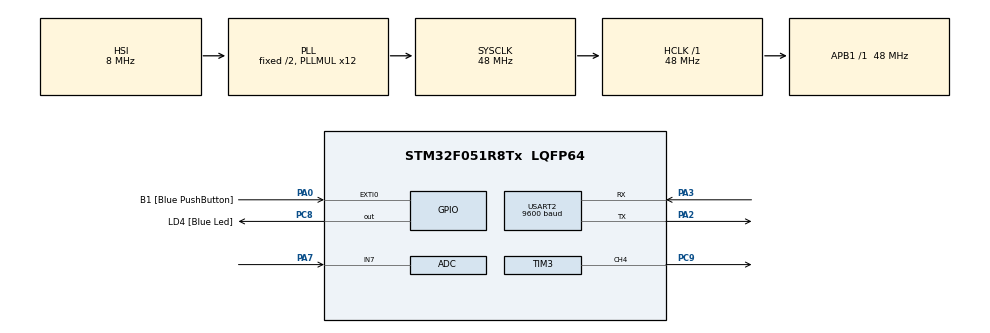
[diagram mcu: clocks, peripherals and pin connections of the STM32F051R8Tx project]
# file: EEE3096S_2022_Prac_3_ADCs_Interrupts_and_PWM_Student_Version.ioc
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Dma.ADC.1.Direction=DMA_PERIPH_TO_MEMORY
Dma.ADC.1.Instance=DMA1_Channel1
Dma.ADC.1.MemDataAlignment=DMA_MDATAALIGN_HALFWORD
Dma.ADC.1.MemInc=DMA_MINC_ENABLE
Dma.ADC.1.Mode=DMA_NORMAL
Dma.ADC.1.PeriphDataAlignment=DMA_PDATAALIGN_HALFWORD
Dma.ADC.1.PeriphInc=DMA_PINC_DISABLE
Dma.ADC.1.Priority=DMA_PRIORITY_LOW
Dma.Request0=USART2_TX
Dma.Request1=ADC
Dma.USART2_TX.0.Direction=DMA_MEMORY_TO_PERIPH
Dma.USART2_TX.0.Instance=DMA1_Channel4
Dma.USART2_TX.0.MemDataAlignment=DMA_MDATAALIGN_BYTE
Dma.USART2_TX.0.MemInc=DMA_MINC_ENABLE
Dma.USART2_TX.0.Mode=DMA_NORMAL
Dma.USART2_TX.0.PeriphDataAlignment=DMA_PDATAALIGN_BYTE
Dma.USART2_TX.0.PeriphInc=DMA_PINC_DISABLE
Dma.USART2_TX.0.Priority=DMA_PRIORITY_LOW
Mcu.Family=STM32F0
Mcu.Name=STM32F051R8Tx
Mcu.Package=LQFP64
NVIC.ADC1_COMP_IRQn=true\:0\:0\:false\:false\:true\:true\:true\:true
NVIC.DMA1_Channel1_IRQn=true\:0\:0\:false\:false\:true\:false\:true\:true
NVIC.DMA1_Channel4_5_IRQn=true\:0\:0\:false\:false\:true\:false\:true\:true
NVIC.EXTI0_1_IRQn=true\:0\:0\:false\:false\:true\:true\:true\:true
NVIC.USART2_IRQn=true\:0\:0\:false\:false\:true\:true\:true\:true
PA0.GPIO_Label=B1 [Blue PushButton]
PA0.GPIO_ModeDefaultEXTI=GPIO_MODE_IT_FALLING
PA0.Signal=GPXTI0
PA13.GPIO_Label=SWDIO
PA13.Mode=Serial_Wire
PA13.Signal=SYS_SWDIO
PA14.GPIO_Label=SWCLK
PA14.Mode=Serial_Wire
PA14.Signal=SYS_SWCLK
PA2.Mode=Asynchronous
PA2.Signal=USART2_TX
PA3.Mode=Asynchronous
PA3.Signal=USART2_RX
PA7.Mode=IN7
PA7.Signal=ADC_IN7
PB6.Signal=I2C1_SCL
PB7.Signal=I2C1_SDA
PC8.GPIO_Label=LD4 [Blue Led]
PC8.Signal=GPIO_Output
PC9.Signal=S_TIM3_CH4
PF0-OSC_IN.Mode=HSE-External-Oscillator
PF0-OSC_IN.Signal=RCC_OSC_IN
PF1-OSC_OUT.Mode=HSE-External-Oscillator
PF1-OSC_OUT.Signal=RCC_OSC_OUT
ProjectManager.HeapSize=0x200
ProjectManager.StackSize=0x400
ProjectManager.TargetToolchain=STM32CubeIDE
RCC.AHBFreq_Value=48000000
RCC.APB1Freq_Value=48000000
RCC.APB1TimFreq_Value=48000000
RCC.HCLKFreq_Value=48000000
RCC.PLLMUL=RCC_PLL_MUL12
RCC.SYSCLKFreq_VALUE=48000000
RCC.SYSCLKSource=RCC_SYSCLKSOURCE_PLLCLK
SH.S_TIM3_CH4.0=TIM3_CH4,PWM Generation4 CH4
TIM3.AutoReloadPreload=TIM_AUTORELOAD_PRELOAD_ENABLE
TIM3.Channel-PWM\ Generation4\ CH4=TIM_CHANNEL_4
TIM3.Period=47999
USART2.BaudRate=9600
USART2.VirtualMode-Asynchronous=VM_ASYNC
VP_TIM3_VS_ClockSourceINT.Mode=Internal
board=STM32F0DISCOVERY

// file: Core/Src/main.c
/* USER CODE BEGIN Header */
/**
*******************************************************
Info:		STM32 ADCs, GPIO Interrupts and PWM with HAL
Author:		Amaan Vally
*******************************************************
In this practical you will learn to use the ADC on the STM32 using the HAL.
Here, we will be measuring the voltage on a potentiometer and using its value
to adjust the brightness of the on board LEDs. We set up an interrupt to switch the
display between the blue and green LEDs.

Code is also provided to send data from the STM32 to other devices using UART protocol
by using HAL. You will need Putty or a Python script to read from the serial port on your PC.

UART Connections are as follows: 5V->5V GND->GND RXD->PA2 TXD->PA3(unused).
Open device manager and go to Ports. Plug in the USB connector with the STM powered on.
Check the port number (COMx). Open up Putty and create a new Serial session on that COMx
with baud rate of 9600.
  ******************************************************************************
  */
/* USER CODE END Header */
#include "main.h"

/* USER CODE BEGIN Includes */
#include <stdio.h>
#include <stdbool.h>

/* USER CODE END Includes */

ADC_HandleTypeDef hadc;
DMA_HandleTypeDef hdma_adc;

TIM_HandleTypeDef htim3;

UART_HandleTypeDef huart2;
DMA_HandleTypeDef hdma_usart2_tx;

/* USER CODE BEGIN PV */
uint32_t tick = 0;
uint32_t previousTick = 0;

char buff[23];
uint32_t count = 0;
uint32_t parity = 0;
bool button_pressed;
//TO DO:
//TASK 1
//Create global variables for debouncing and delay interval

/* USER CODE END PV */

void SystemClock_Config(void);
static void MX_GPIO_Init(void);
static void MX_DMA_Init(void);
static void MX_USART2_UART_Init(void);
static void MX_ADC_Init(void);
static void MX_TIM3_Init(void);
/* USER CODE BEGIN PFP */
void EXTI0_1_IRQHandler(void);
uint32_t pollADC(void);

/* USER CODE END PFP */

int main(void)
{

  /* MCU Configuration--------------------------------------------------------*/

  /* Reset of all peripherals, Initializes the Flash interface and the Systick. */
  HAL_Init();

  /* Configure the system clock */
  SystemClock_Config();

  /* Initialize all configured peripherals */
  MX_GPIO_Init();
  MX_DMA_Init();
  MX_USART2_UART_Init();
  MX_ADC_Init();
  MX_TIM3_Init();
  /* USER CODE BEGIN 2 */

  //TO DO:
  //Create variables needed in while loop

  HAL_TIM_PWM_Start(&htim3, TIM_CHANNEL_4); //Start the PWM on TIM3 Channel 4 (Green LED)
  /* USER CODE END 2 */

  /* Infinite loop */
  /* USER CODE BEGIN WHILE */
  while (1)
  {
	  //int starttime = HAL_GetTick();

	  if (button_pressed) {

		  int delay = 510;
		  uint32_t data = pollADC();
		  //uint32_t data = 0b010101010101;
		  uint32_t count1 = count;
		  int oneCount = 0;

		//Build in start bit
		buff[0] = '1';

		//Build in data
		int loop_count = 12;
	    int what_bit_i_am_testing = 0;
		while (what_bit_i_am_testing < 12) {
			if (data & 0x01) {
				buff[loop_count] = '1';
				oneCount += 1;

			}
			  else {
				buff[loop_count] = '0';
			  }

			  what_bit_i_am_testing++;
			  data = data >> 1;
			  loop_count--;
			}

		//Build in parity bit
		if (oneCount%2 == 0) {
			buff[13] = '0';
		} else {
			buff[13] = '1';
		}

		//Build in count
		loop_count = 21;
	    what_bit_i_am_testing = 0;
		while (what_bit_i_am_testing < 8) {
			if (count1 & 0x01) {
				buff[loop_count] = '1';

			}
			  else {
				buff[loop_count] = '0';
			  }

			  what_bit_i_am_testing++;
			  count1 = count1 >> 1;
			  loop_count--;
			}

		//Build in end bit
		buff[22] = '1';

		HAL_UART_Transmit(&huart2, (uint8_t *)&buff, sizeof(buff), 1000);

		//Send data
		for (int j = 0; j <= 22; j++) {
			if (buff[j] == '1') {
				HAL_GPIO_WritePin(GPIOF, GPIO_PIN_6, 1);
				HAL_GPIO_WritePin(GPIOC, GPIO_PIN_8, 1);
			    HAL_Delay(delay);
			    HAL_GPIO_WritePin(GPIOF, GPIO_PIN_6, 0);
			    HAL_GPIO_WritePin(GPIOC, GPIO_PIN_8, 0);
			} else {
				HAL_Delay(delay);
			}

		}

		count += 1;
		button_pressed = false;
	  }

    /* USER CODE END WHILE */

  }
}

void SystemClock_Config(void)
{
  RCC_OscInitTypeDef RCC_OscInitStruct = {0};
  RCC_ClkInitTypeDef RCC_ClkInitStruct = {0};

  /** Initializes the RCC Oscillators according to the specified parameters
  * in the RCC_OscInitTypeDef structure.
  */
  RCC_OscInitStruct.OscillatorType = RCC_OSCILLATORTYPE_HSI|RCC_OSCILLATORTYPE_HSI14;
  RCC_OscInitStruct.HSIState = RCC_HSI_ON;
  RCC_OscInitStruct.HSI14State = RCC_HSI14_ON;
  RCC_OscInitStruct.HSICalibrationValue = RCC_HSICALIBRATION_DEFAULT;
  RCC_OscInitStruct.HSI14CalibrationValue = 16;
  RCC_OscInitStruct.PLL.PLLState = RCC_PLL_ON;
  RCC_OscInitStruct.PLL.PLLSource = RCC_PLLSOURCE_HSI;
  RCC_OscInitStruct.PLL.PLLMUL = RCC_PLL_MUL12;
  RCC_OscInitStruct.PLL.PREDIV = RCC_PREDIV_DIV1;
  if (HAL_RCC_OscConfig(&RCC_OscInitStruct) != HAL_OK)
  {
    Error_Handler();
  }

  /** Initializes the CPU, AHB and APB buses clocks
  */
  RCC_ClkInitStruct.ClockType = RCC_CLOCKTYPE_HCLK|RCC_CLOCKTYPE_SYSCLK
                              |RCC_CLOCKTYPE_PCLK1;
  RCC_ClkInitStruct.SYSCLKSource = RCC_SYSCLKSOURCE_PLLCLK;
  RCC_ClkInitStruct.AHBCLKDivider = RCC_SYSCLK_DIV1;
  RCC_ClkInitStruct.APB1CLKDivider = RCC_HCLK_DIV1;

  if (HAL_RCC_ClockConfig(&RCC_ClkInitStruct, FLASH_LATENCY_1) != HAL_OK)
  {
    Error_Handler();
  }
}

static void MX_ADC_Init(void)
{

  ADC_ChannelConfTypeDef sConfig = {0};

  /** Configure the global features of the ADC (Clock, Resolution, Data Alignment and number of conversion)
  */
  hadc.Instance = ADC1;
  hadc.Init.ClockPrescaler = ADC_CLOCK_ASYNC_DIV1;
  hadc.Init.Resolution = ADC_RESOLUTION_12B;
  hadc.Init.DataAlign = ADC_DATAALIGN_RIGHT;
  hadc.Init.ScanConvMode = ADC_SCAN_DIRECTION_FORWARD;
  hadc.Init.EOCSelection = ADC_EOC_SINGLE_CONV;
  hadc.Init.LowPowerAutoWait = DISABLE;
  hadc.Init.LowPowerAutoPowerOff = DISABLE;
  hadc.Init.ContinuousConvMode = DISABLE;
  hadc.Init.DiscontinuousConvMode = DISABLE;
  hadc.Init.ExternalTrigConv = ADC_SOFTWARE_START;
  hadc.Init.ExternalTrigConvEdge = ADC_EXTERNALTRIGCONVEDGE_NONE;
  hadc.Init.DMAContinuousRequests = DISABLE;
  hadc.Init.Overrun = ADC_OVR_DATA_PRESERVED;
  if (HAL_ADC_Init(&hadc) != HAL_OK)
  {
    Error_Handler();
  }

  /** Configure for the selected ADC regular channel to be converted.
  */
  sConfig.Channel = ADC_CHANNEL_7;
  sConfig.Rank = ADC_RANK_CHANNEL_NUMBER;
  sConfig.SamplingTime = ADC_SAMPLETIME_1CYCLE_5;
  if (HAL_ADC_ConfigChannel(&hadc, &sConfig) != HAL_OK)
  {
    Error_Handler();
  }

}

static void MX_TIM3_Init(void)
{

  TIM_ClockConfigTypeDef sClockSourceConfig = {0};
  TIM_MasterConfigTypeDef sMasterConfig = {0};
  TIM_OC_InitTypeDef sConfigOC = {0};

  htim3.Instance = TIM3;
  htim3.Init.Prescaler = 0;
  htim3.Init.CounterMode = TIM_COUNTERMODE_UP;
  htim3.Init.Period = 47999;
  htim3.Init.ClockDivision = TIM_CLOCKDIVISION_DIV1;
  htim3.Init.AutoReloadPreload = TIM_AUTORELOAD_PRELOAD_ENABLE;
  if (HAL_TIM_Base_Init(&htim3) != HAL_OK)
  {
    Error_Handler();
  }
  sClockSourceConfig.ClockSource = TIM_CLOCKSOURCE_INTERNAL;
  if (HAL_TIM_ConfigClockSource(&htim3, &sClockSourceConfig) != HAL_OK)
  {
    Error_Handler();
  }
  if (HAL_TIM_PWM_Init(&htim3) != HAL_OK)
  {
    Error_Handler();
  }
  sMasterConfig.MasterOutputTrigger = TIM_TRGO_RESET;
  sMasterConfig.MasterSlaveMode = TIM_MASTERSLAVEMODE_DISABLE;
  if (HAL_TIMEx_MasterConfigSynchronization(&htim3, &sMasterConfig) != HAL_OK)
  {
    Error_Handler();
  }
  sConfigOC.OCMode = TIM_OCMODE_PWM1;
  sConfigOC.Pulse = 0;
  sConfigOC.OCPolarity = TIM_OCPOLARITY_HIGH;
  sConfigOC.OCFastMode = TIM_OCFAST_DISABLE;
  if (HAL_TIM_PWM_ConfigChannel(&htim3, &sConfigOC, TIM_CHANNEL_4) != HAL_OK)
  {
    Error_Handler();
  }
  HAL_TIM_MspPostInit(&htim3);

}

static void MX_USART2_UART_Init(void)
{

  huart2.Instance = USART2;
  huart2.Init.BaudRate = 9600;
  huart2.Init.WordLength = UART_WORDLENGTH_8B;
  huart2.Init.StopBits = UART_STOPBITS_1;
  huart2.Init.Parity = UART_PARITY_NONE;
  huart2.Init.Mode = UART_MODE_TX_RX;
  huart2.Init.HwFlowCtl = UART_HWCONTROL_NONE;
  huart2.Init.OverSampling = UART_OVERSAMPLING_16;
  huart2.Init.OneBitSampling = UART_ONE_BIT_SAMPLE_DISABLE;
  huart2.AdvancedInit.AdvFeatureInit = UART_ADVFEATURE_NO_INIT;
  if (HAL_UART_Init(&huart2) != HAL_OK)
  {
    Error_Handler();
  }

}

static void MX_DMA_Init(void)
{

  /* DMA controller clock enable */
  __HAL_RCC_DMA1_CLK_ENABLE();

  /* DMA interrupt init */
  /* DMA1_Channel1_IRQn interrupt configuration */
  HAL_NVIC_SetPriority(DMA1_Channel1_IRQn, 0, 0);
  HAL_NVIC_EnableIRQ(DMA1_Channel1_IRQn);
  /* DMA1_Channel4_5_IRQn interrupt configuration */
  HAL_NVIC_SetPriority(DMA1_Channel4_5_IRQn, 0, 0);
  HAL_NVIC_EnableIRQ(DMA1_Channel4_5_IRQn);

}

static void MX_GPIO_Init(void)
{
  GPIO_InitTypeDef GPIO_InitStruct = {0};

  /* GPIO Ports Clock Enable */
  __HAL_RCC_GPIOF_CLK_ENABLE();
  __HAL_RCC_GPIOA_CLK_ENABLE();
  __HAL_RCC_GPIOC_CLK_ENABLE();
  __HAL_RCC_GPIOB_CLK_ENABLE();

  /*Configure GPIO pin Output Level */
  HAL_GPIO_WritePin(LD4_GPIO_Port, LD4_Pin, GPIO_PIN_RESET);

  /*Configure GPIO pin : B1_Pin */
  GPIO_InitStruct.Pin = B1_Pin;
  GPIO_InitStruct.Mode = GPIO_MODE_IT_FALLING;
  GPIO_InitStruct.Pull = GPIO_NOPULL;
  HAL_GPIO_Init(B1_GPIO_Port, &GPIO_InitStruct);

  /*Configure GPIO pin : LD4_Pin */
  GPIO_InitStruct.Pin = LD4_Pin;
  GPIO_InitStruct.Mode = GPIO_MODE_OUTPUT_PP;
  GPIO_InitStruct.Pull = GPIO_NOPULL;
  GPIO_InitStruct.Speed = GPIO_SPEED_FREQ_LOW;
  HAL_GPIO_Init(LD4_GPIO_Port, &GPIO_InitStruct);

  /*Configure GPIO pin : LD4_Pin */
    GPIO_InitStruct.Pin = GPIO_PIN_6;
    GPIO_InitStruct.Mode = GPIO_MODE_OUTPUT_PP;
    GPIO_InitStruct.Pull = GPIO_NOPULL;
    GPIO_InitStruct.Speed = GPIO_SPEED_FREQ_LOW;
    HAL_GPIO_Init(GPIOF, &GPIO_InitStruct);

  /*Configure GPIO pins : PB6 PB7 */
  GPIO_InitStruct.Pin = GPIO_PIN_6|GPIO_PIN_7;
  GPIO_InitStruct.Mode = GPIO_MODE_AF_OD;
  GPIO_InitStruct.Pull = GPIO_NOPULL;
  GPIO_InitStruct.Speed = GPIO_SPEED_FREQ_HIGH;
  GPIO_InitStruct.Alternate = GPIO_AF1_I2C1;
  HAL_GPIO_Init(GPIOB, &GPIO_InitStruct);

  /* EXTI interrupt init*/
  HAL_NVIC_SetPriority(EXTI0_1_IRQn, 0, 0);
  HAL_NVIC_EnableIRQ(EXTI0_1_IRQn);

}

/* USER CODE BEGIN 4 */
void EXTI0_1_IRQHandler(void)
{

	tick = HAL_GetTick();

	if (tick - previousTick > 50)
	{
		previousTick = tick;

		button_pressed = true;

		//HAL_GPIO_TogglePin(GPIOF, GPIO_PIN_6);
	} else {

	}

	HAL_GPIO_EXTI_IRQHandler(B1_Pin); // Clear interrupt flags
}

uint32_t pollADC(void){
	//TO DO:
	//TASK 2
	// Complete the function body
	HAL_ADC_Start(&hadc);
	HAL_ADC_GetValue(&hadc);
	uint32_t val = HAL_ADC_GetValue(&hadc);
	HAL_ADC_Stop(&hadc);
	return val;
}

/* USER CODE END 4 */

void Error_Handler(void)
{
  __disable_irq();
  while (1)
  {
  }
}
